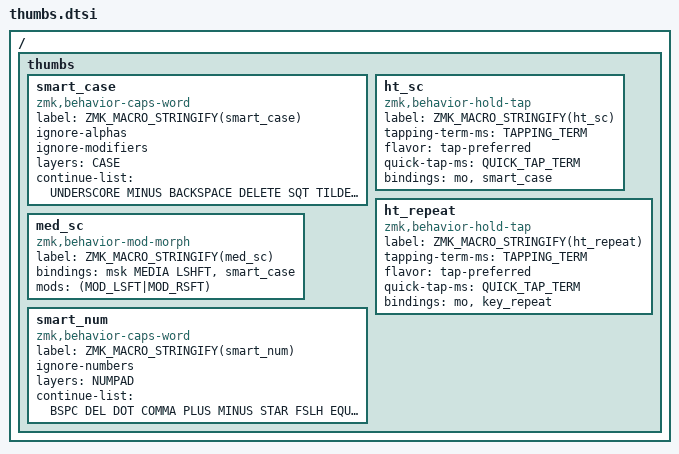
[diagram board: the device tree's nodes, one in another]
/*
*
* Copyright (c) 2022 Rafael Romão
* SPDX-License-Identifier: MIT
*
*/

/ {
    thumbs {
        smart_case: smart_case {
            compatible = "zmk,behavior-caps-word";
            label = ZMK_MACRO_STRINGIFY(smart_case);
            ignore-alphas;
            ignore-modifiers;
			#binding-cells = <0>;  
            layers = <CASE>;
            continue-list = <UNDERSCORE MINUS BACKSPACE DELETE SQT TILDE CARET GRAVE>;
        };

        ht_sc: ht_sc {
            compatible = "zmk,behavior-hold-tap";
            label = ZMK_MACRO_STRINGIFY(ht_sc);
            #binding-cells = <2>;
            tapping-term-ms = <TAPPING_TERM>;
            flavor = "tap-preferred";
            quick-tap-ms = <QUICK_TAP_TERM>;
            bindings = <&mo>, <&smart_case>;
        };

        ht_repeat: ht_repeat {
            compatible = "zmk,behavior-hold-tap";
            label = ZMK_MACRO_STRINGIFY(ht_repeat);
            #binding-cells = <2>;
            tapping-term-ms = <TAPPING_TERM>;
            flavor = "tap-preferred";
            quick-tap-ms = <QUICK_TAP_TERM>;
            bindings = <&mo>, <&key_repeat>;
        };

        med_sc: med_sc {
            compatible = "zmk,behavior-mod-morph";
            label = ZMK_MACRO_STRINGIFY(med_sc);
            #binding-cells = <0>;
            bindings = <&msk MEDIA LSHFT>, <&smart_case>;
            mods = <(MOD_LSFT|MOD_RSFT)>;
        };

        smart_num: smart_num {
            compatible = "zmk,behavior-caps-word";
            label = ZMK_MACRO_STRINGIFY(smart_num);
            ignore-numbers;
			#binding-cells = <0>;
            layers = <NUMPAD>;
            continue-list = <BSPC DEL DOT COMMA PLUS MINUS STAR FSLH EQUAL>;
        };
    };
};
